# LAN9255ZMX019 register map
Vendor: Microchip
Registers are 32-bit, read-write, reset 0x0 unless marked. A register's access mark holds for its fields unless they carry their own. Addresses are absolute, and some are shared; only a register's first bit layout is shown; [hi:lo] are bit positions; {n}, {i} and the like mark numbered series; 'fields as' and 'values as' point back to an identical list.

## TC5
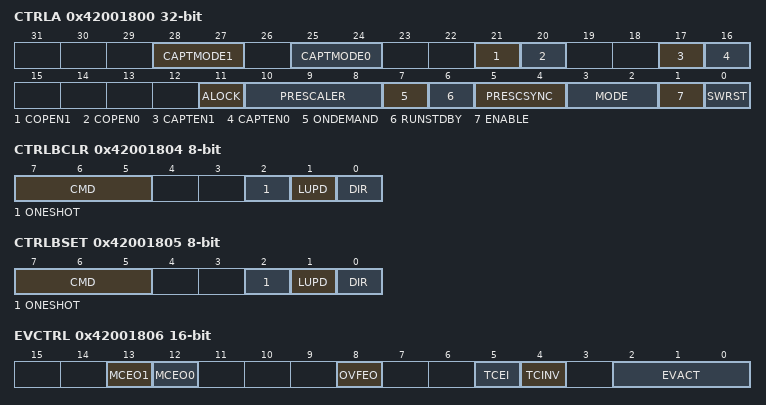
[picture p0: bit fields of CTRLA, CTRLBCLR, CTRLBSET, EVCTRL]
0x42001800 CTRLA
  [28:27] CAPTMODE1 — Capture mode Channel 1
    0=DEFAULT (Default capture); 1=CAPTMIN (Minimum capture); 2=CAPTMAX (Maximum capture)
  [25:24] CAPTMODE0 — Capture Mode Channel 0
    values as CAPTMODE1
  [21] COPEN1 — Capture On Pin 1 Enable
  [20] COPEN0 — Capture On Pin 0 Enable
  [17] CAPTEN1 — Capture Channel 1 Enable
  [16] CAPTEN0 — Capture Channel 0 Enable
  [11] ALOCK — Auto Lock
  [10:8] PRESCALER
    0=DIV1 (Prescaler: GCLK_TC); 1=DIV2 (Prescaler: GCLK_TC/2); 2=DIV4 (Prescaler: GCLK_TC/4); 3=DIV8 (Prescaler: GCLK_TC/8); 4=DIV16 (Prescaler: GCLK_TC/16); 5=DIV64 (Prescaler: GCLK_TC/64); 6=DIV256 (Prescaler: GCLK_TC/256); 7=DIV1024 (Prescaler: GCLK_TC/1024)
  [7] ONDEMAND — Clock On Demand
  [6] RUNSTDBY — Run during Standby
  [5:4] PRESCSYNC — Prescaler and Counter Synchronization
    0=GCLK (Reload or reset the counter on next generic clock); 1=PRESC (Reload or reset the counter on next prescaler clock); 2=RESYNC (Reload or reset the counter on next generic clock and reset the prescaler counter)
  [3:2] MODE — Timer Counter Mode
    0=COUNT16 (Counter in 16-bit mode); 1=COUNT8 (Counter in 8-bit mode); 2=COUNT32 (Counter in 32-bit mode)
  [1] ENABLE
  [0] SWRST — Software Reset
0x42001804 CTRLBCLR 8-bit
  [7:5] CMD — Command
    0=NONE (No action); 1=RETRIGGER (Force a start, restart or retrigger); 2=STOP (Force a stop); 3=UPDATE (Force update of double-buffered register); 4=READSYNC (Force a read synchronization of COUNT)
  [2] ONESHOT — One-Shot on Counter
  [1] LUPD — Lock Update
  [0] DIR — Counter Direction
0x42001805 CTRLBSET 8-bit
  fields as CTRLBCLR
0x42001806 EVCTRL 16-bit
  [13] MCEO1 — MC Event Output Enable 1
  [12] MCEO0 — MC Event Output Enable 0
  [8] OVFEO — Event Output Enable
  [5] TCEI — TC Event Enable
  [4] TCINV — TC Event Input Polarity
  [2:0] EVACT — Event Action
    0=OFF (Event action disabled); 1=RETRIGGER (Start, restart or retrigger TC on event); 2=COUNT (Count on event); 3=START (Start TC on event); 4=STAMP (Time stamp capture); 5=PPW (Period catured in CC0, pulse width in CC1); 6=PWP (Period catured in CC1, pulse width in CC0); 7=PW (Pulse width capture)
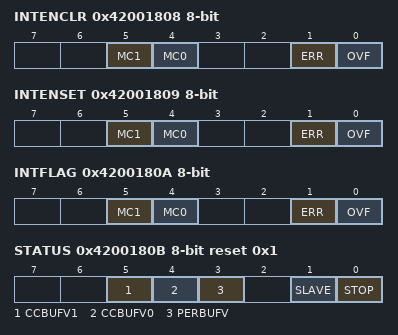
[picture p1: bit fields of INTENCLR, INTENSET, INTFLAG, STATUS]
0x42001808 INTENCLR 8-bit
  [5] MC1 — MC Interrupt Disable 1
  [4] MC0 — MC Interrupt Disable 0
  [1] ERR — ERR Interrupt Disable
  [0] OVF — OVF Interrupt Disable
0x42001809 INTENSET 8-bit
  [5] MC1 — MC Interrupt Enable 1
  [4] MC0 — MC Interrupt Enable 0
  [1] ERR — ERR Interrupt Enable
  [0] OVF — OVF Interrupt Enable
0x4200180A INTFLAG 8-bit
  [5] MC1 — MC Interrupt Flag 1
  [4] MC0 — MC Interrupt Flag 0
  [1] ERR — ERR Interrupt Flag
  [0] OVF — OVF Interrupt Flag
0x4200180B STATUS 8-bit reset 0x1
  [5] CCBUFV1 — Compare channel buffer 1 valid
  [4] CCBUFV0 — Compare channel buffer 0 valid
  [3] PERBUFV — Synchronization Busy Status
  [1] SLAVE — Slave Status Flag
  [0] STOP — Stop Status Flag
0x4200180C WAVE 8-bit
  [1:0] WAVEGEN — Waveform Generation Mode
    0=NFRQ (Normal frequency); 1=MFRQ (Match frequency); 2=NPWM (Normal PWM); 3=MPWM (Match PWM)
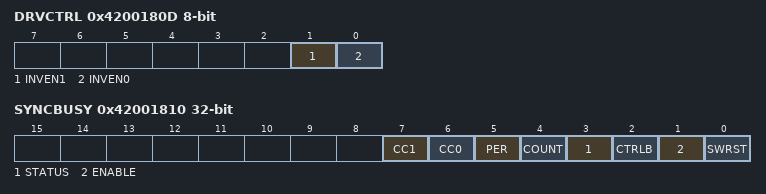
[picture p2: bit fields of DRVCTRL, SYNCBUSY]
0x4200180D DRVCTRL 8-bit
  [1] INVEN1 — Output Waveform Invert Enable 1
  [0] INVEN0 — Output Waveform Invert Enable 0
0x4200180F DBGCTRL 8-bit
  [0] DBGRUN — Run During Debug
0x42001810 SYNCBUSY ro
  [7] CC1 — Compare Channel 1
  [6] CC0 — Compare Channel 0
  [5] PER — Period
  [4] COUNT — Counter
  [3] STATUS
  [2] CTRLB
  [1] ENABLE
  [0] SWRST

## AC
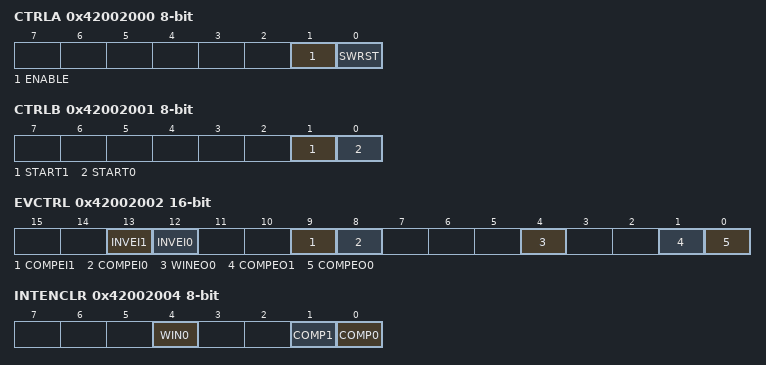
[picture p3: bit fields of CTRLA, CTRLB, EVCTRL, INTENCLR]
0x42002000 CTRLA 8-bit
  [1] ENABLE
  [0] SWRST — Software Reset
0x42002001 CTRLB 8-bit wo
  [1] START1 — Comparator 1 Start Comparison
  [0] START0 — Comparator 0 Start Comparison
0x42002002 EVCTRL 16-bit
  [13] INVEI1 — Comparator 1 Input Event Invert Enable
  [12] INVEI0 — Comparator 0 Input Event Invert Enable
  [9] COMPEI1 — Comparator 1 Event Input Enable
  [8] COMPEI0 — Comparator 0 Event Input Enable
  [4] WINEO0 — Window 0 Event Output Enable
  [1] COMPEO1 — Comparator 1 Event Output Enable
  [0] COMPEO0 — Comparator 0 Event Output Enable
0x42002004 INTENCLR 8-bit
  [4] WIN0 — Window 0 Interrupt Enable
  [1] COMP1 — Comparator 1 Interrupt Enable
  [0] COMP0 — Comparator 0 Interrupt Enable
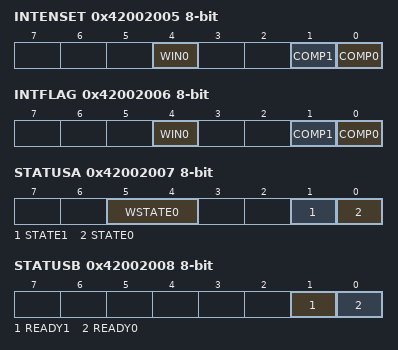
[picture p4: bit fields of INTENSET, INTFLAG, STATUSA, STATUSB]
0x42002005 INTENSET 8-bit
  fields as INTENCLR
0x42002006 INTFLAG 8-bit
  [4] WIN0 — Window 0
  [1] COMP1 — Comparator 1
  [0] COMP0 — Comparator 0
0x42002007 STATUSA 8-bit ro
  [5:4] WSTATE0 — Window 0 Current State
    0=ABOVE (Signal is above window); 1=INSIDE (Signal is inside window); 2=BELOW (Signal is below window)
  [1] STATE1 — Comparator 1 Current State
  [0] STATE0 — Comparator 0 Current State
0x42002008 STATUSB 8-bit ro
  [1] READY1 — Comparator 1 Ready
  [0] READY0 — Comparator 0 Ready
0x42002009 DBGCTRL 8-bit
  [0] DBGRUN — Debug Run
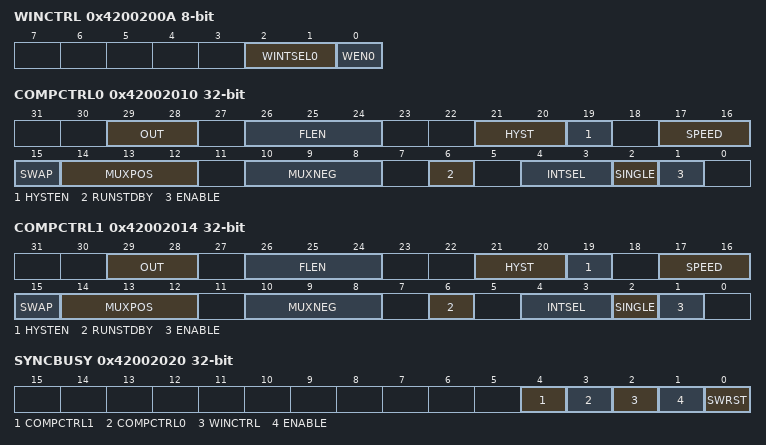
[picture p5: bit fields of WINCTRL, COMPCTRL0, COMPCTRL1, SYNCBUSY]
0x4200200A WINCTRL 8-bit
  [2:1] WINTSEL0 — Window 0 Interrupt Selection
    0=ABOVE (Interrupt on signal above window); 1=INSIDE (Interrupt on signal inside window); 2=BELOW (Interrupt on signal below window); 3=OUTSIDE (Interrupt on signal outside window)
  [0] WEN0 — Window 0 Mode Enable
0x4200200C SCALER0 8-bit
  [5:0] VALUE — Scaler Value
0x4200200D SCALER1 8-bit
  [5:0] VALUE — Scaler Value
0x42002010 COMPCTRL0
  [29:28] OUT — Output
    0=OFF (The output of COMPn is not routed to the COMPn I/O port); 1=ASYNC (The asynchronous output of COMPn is routed to the COMPn I/O port); 2=SYNC (The synchronous output (including filtering) of COMPn is routed to the COMPn I/O port)
  [26:24] FLEN — Filter Length
    0=OFF (No filtering); 1=MAJ3 (3-bit majority function (2 of 3)); 2=MAJ5 (5-bit majority function (3 of 5))
  [21:20] HYST — Hysteresis Level
    0=50mV; 1=100mV; 2=150mV
  [19] HYSTEN — Hysteresis Enable
  [17:16] SPEED — Speed Selection
    3=HIGH (High speed)
  [15] SWAP — Swap Inputs and Invert
  [14:12] MUXPOS — Positive Input Mux Selection
    {v}=PIN{v} (I/O pin {v}) (v=0..3); 4=VSCALE (VDD Scaler)
  [10:8] MUXNEG — Negative Input Mux Selection
    {v}=PIN{v} (I/O pin {v}) (v=0..3); 4=GND (Ground); 5=VSCALE (VDD scaler); 6=BANDGAP (Internal bandgap voltage); 7=DAC (DAC output)
  [6] RUNSTDBY — Run in Standby
  [4:3] INTSEL — Interrupt Selection
    0=TOGGLE (Interrupt on comparator output toggle); 1=RISING (Interrupt on comparator output rising); 2=FALLING (Interrupt on comparator output falling); 3=EOC (Interrupt on end of comparison (single-shot mode only))
  [2] SINGLE — Single-Shot Mode
  [1] ENABLE
0x42002014 COMPCTRL1
  fields as COMPCTRL0
0x42002020 SYNCBUSY ro
  [4] COMPCTRL1 — COMPCTRL 1 Synchronization Busy
  [3] COMPCTRL0 — COMPCTRL 0 Synchronization Busy
  [2] WINCTRL — WINCTRL Synchronization Busy
  [1] ENABLE — Enable Synchronization Busy
  [0] SWRST — Software Reset Synchronization Busy
0x42002024 CALIB 16-bit reset 0x101
  [1:0] BIAS0 — COMP0/1 Bias Scaling
